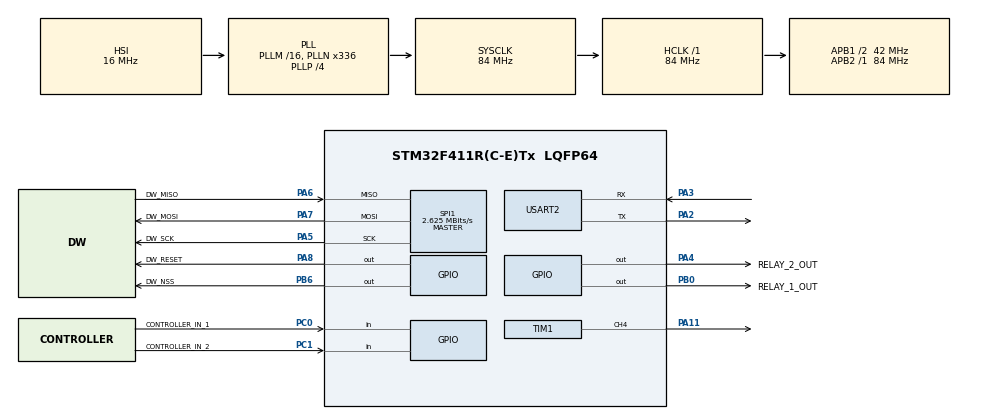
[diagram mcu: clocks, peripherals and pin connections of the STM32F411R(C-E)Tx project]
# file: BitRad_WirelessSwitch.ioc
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Mcu.Family=STM32F4
Mcu.Name=STM32F411R(C-E)Tx
Mcu.Package=LQFP64
NVIC.PriorityGroup=NVIC_PRIORITYGROUP_0
PA11.Signal=S_TIM1_CH4
PA13.GPIO_Label=TMS
PA13.Signal=SYS_JTMS-SWDIO
PA2.Mode=Asynchronous
PA2.Signal=USART2_TX
PA3.Mode=Asynchronous
PA3.Signal=USART2_RX
PA4.GPIO_Label=RELAY_2_OUT
PA4.Signal=GPIO_Output
PA5.GPIO_Label=DW_SCK
PA5.Mode=Full_Duplex_Master
PA5.Signal=SPI1_SCK
PA6.GPIO_Label=DW_MISO
PA6.Mode=Full_Duplex_Master
PA6.Signal=SPI1_MISO
PA7.GPIO_Label=DW_MOSI
PA7.Mode=Full_Duplex_Master
PA7.Signal=SPI1_MOSI
PA8.GPIO_Label=DW_RESET
PA8.GPIO_ModeDefaultOutputPP=GPIO_MODE_OUTPUT_OD
PA8.GPIO_PuPd=GPIO_NOPULL
PA8.GPIO_Speed=GPIO_SPEED_FREQ_HIGH
PA8.PinState=GPIO_PIN_SET
PA8.Signal=GPIO_Output
PB0.GPIO_Label=RELAY_1_OUT
PB0.Signal=GPIO_Output
PB6.GPIO_Label=DW_NSS
PB6.Signal=GPIO_Output
PC0.GPIO_Label=CONTROLLER_IN_1
PC0.GPIO_PuPd=GPIO_PULLDOWN
PC0.Signal=GPIO_Input
PC1.GPIO_Label=CONTROLLER_IN_2
PC1.GPIO_PuPd=GPIO_PULLDOWN
PC1.Signal=GPIO_Input
ProjectManager.HeapSize=0x200
ProjectManager.StackSize=0x400
ProjectManager.TargetToolchain=STM32CubeIDE
RCC.48MHZClocksFreq_Value=84000000
RCC.AHBFreq_Value=84000000
RCC.APB1CLKDivider=RCC_HCLK_DIV2
RCC.APB1Freq_Value=42000000
RCC.APB1TimFreq_Value=84000000
RCC.APB2Freq_Value=84000000
RCC.APB2TimFreq_Value=84000000
RCC.CortexFreq_Value=84000000
RCC.FLatency-AdvancedSettings=FLASH_LATENCY_2
RCC.HCLKFreq_Value=84000000
RCC.HSE_VALUE=8000000
RCC.HSI_VALUE=16000000
RCC.LSE_VALUE=32768
RCC.PLLN=336
RCC.PLLP=RCC_PLLP_DIV4
RCC.SYSCLKFreq_VALUE=84000000
RCC.SYSCLKSource=RCC_SYSCLKSOURCE_PLLCLK
RCC.VCOOutputFreq_Value=336000000
SH.S_TIM1_CH4.0=TIM1_CH4,PWM Generation4 CH4
SPI1.BaudRatePrescaler=SPI_BAUDRATEPRESCALER_32
SPI1.CalculateBaudRate=2.625 MBits/s
SPI1.Direction=SPI_DIRECTION_2LINES
SPI1.Mode=SPI_MODE_MASTER
SPI1.VirtualType=VM_MASTER
TIM1.Channel-PWM\ Generation4\ CH4=TIM_CHANNEL_4
USART2.VirtualMode=VM_ASYNC
board=NUCLEO-F411RE

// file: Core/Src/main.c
/* USER CODE BEGIN Header */
/**
  ******************************************************************************
  * @file           : main.c
  * @brief          : Main program body
  ******************************************************************************
  * @attention
  *
  * Copyright (c) 2022 STMicroelectronics.
  * All rights reserved.
  *
  * This software is licensed under terms that can be found in the LICENSE file
  * in the root directory of this software component.
  * If no LICENSE file comes with this software, it is provided AS-IS.
  *
  ******************************************************************************
  */
/* USER CODE END Header */
#include "main.h"
#include "spi.h"
#include "tim.h"
#include "usart.h"
#include "gpio.h"

/* USER CODE BEGIN Includes */
#include <stdio.h>
#include "uwb_master.h"
#include "uwb_slave.h"
#include "error_led.h"
/* USER CODE END Includes */

void SystemClock_Config(void);

int main(void)
{

  /* MCU Configuration--------------------------------------------------------*/

  /* Reset of all peripherals, Initializes the Flash interface and the Systick. */
  HAL_Init();

  /* Configure the system clock */
  SystemClock_Config();

  /* Initialize all configured peripherals */
  MX_GPIO_Init();
  MX_SPI1_Init();
  MX_USART2_UART_Init();
  MX_TIM1_Init();
  /* USER CODE BEGIN 2 */
  initErrorLed();

  // When flashing STM boards (master and slave), One of the following
  // function calls will be commented accordingly
//  uwb_slave(); // Acts as the slave (066BFF535157808667101914)
  uwb_master(); // Acts as the master

  /* USER CODE END 2 */

  /* Infinite loop */
  while (1)
  {

  }
}

void SystemClock_Config(void)
{
  RCC_OscInitTypeDef RCC_OscInitStruct = {0};
  RCC_ClkInitTypeDef RCC_ClkInitStruct = {0};

  /** Configure the main internal regulator output voltage
  */
  __HAL_RCC_PWR_CLK_ENABLE();
  __HAL_PWR_VOLTAGESCALING_CONFIG(PWR_REGULATOR_VOLTAGE_SCALE1);

  /** Initializes the RCC Oscillators according to the specified parameters
  * in the RCC_OscInitTypeDef structure.
  */
  RCC_OscInitStruct.OscillatorType = RCC_OSCILLATORTYPE_HSI;
  RCC_OscInitStruct.HSIState = RCC_HSI_ON;
  RCC_OscInitStruct.HSICalibrationValue = RCC_HSICALIBRATION_DEFAULT;
  RCC_OscInitStruct.PLL.PLLState = RCC_PLL_ON;
  RCC_OscInitStruct.PLL.PLLSource = RCC_PLLSOURCE_HSI;
  RCC_OscInitStruct.PLL.PLLM = 16;
  RCC_OscInitStruct.PLL.PLLN = 336;
  RCC_OscInitStruct.PLL.PLLP = RCC_PLLP_DIV4;
  RCC_OscInitStruct.PLL.PLLQ = 4;
  if (HAL_RCC_OscConfig(&RCC_OscInitStruct) != HAL_OK)
  {
    Error_Handler();
  }

  /** Initializes the CPU, AHB and APB buses clocks
  */
  RCC_ClkInitStruct.ClockType = RCC_CLOCKTYPE_HCLK|RCC_CLOCKTYPE_SYSCLK
                              |RCC_CLOCKTYPE_PCLK1|RCC_CLOCKTYPE_PCLK2;
  RCC_ClkInitStruct.SYSCLKSource = RCC_SYSCLKSOURCE_PLLCLK;
  RCC_ClkInitStruct.AHBCLKDivider = RCC_SYSCLK_DIV1;
  RCC_ClkInitStruct.APB1CLKDivider = RCC_HCLK_DIV2;
  RCC_ClkInitStruct.APB2CLKDivider = RCC_HCLK_DIV1;

  if (HAL_RCC_ClockConfig(&RCC_ClkInitStruct, FLASH_LATENCY_2) != HAL_OK)
  {
    Error_Handler();
  }
}

void Error_Handler(void)
{
  __disable_irq();
  while (1)
  {
  }
}
